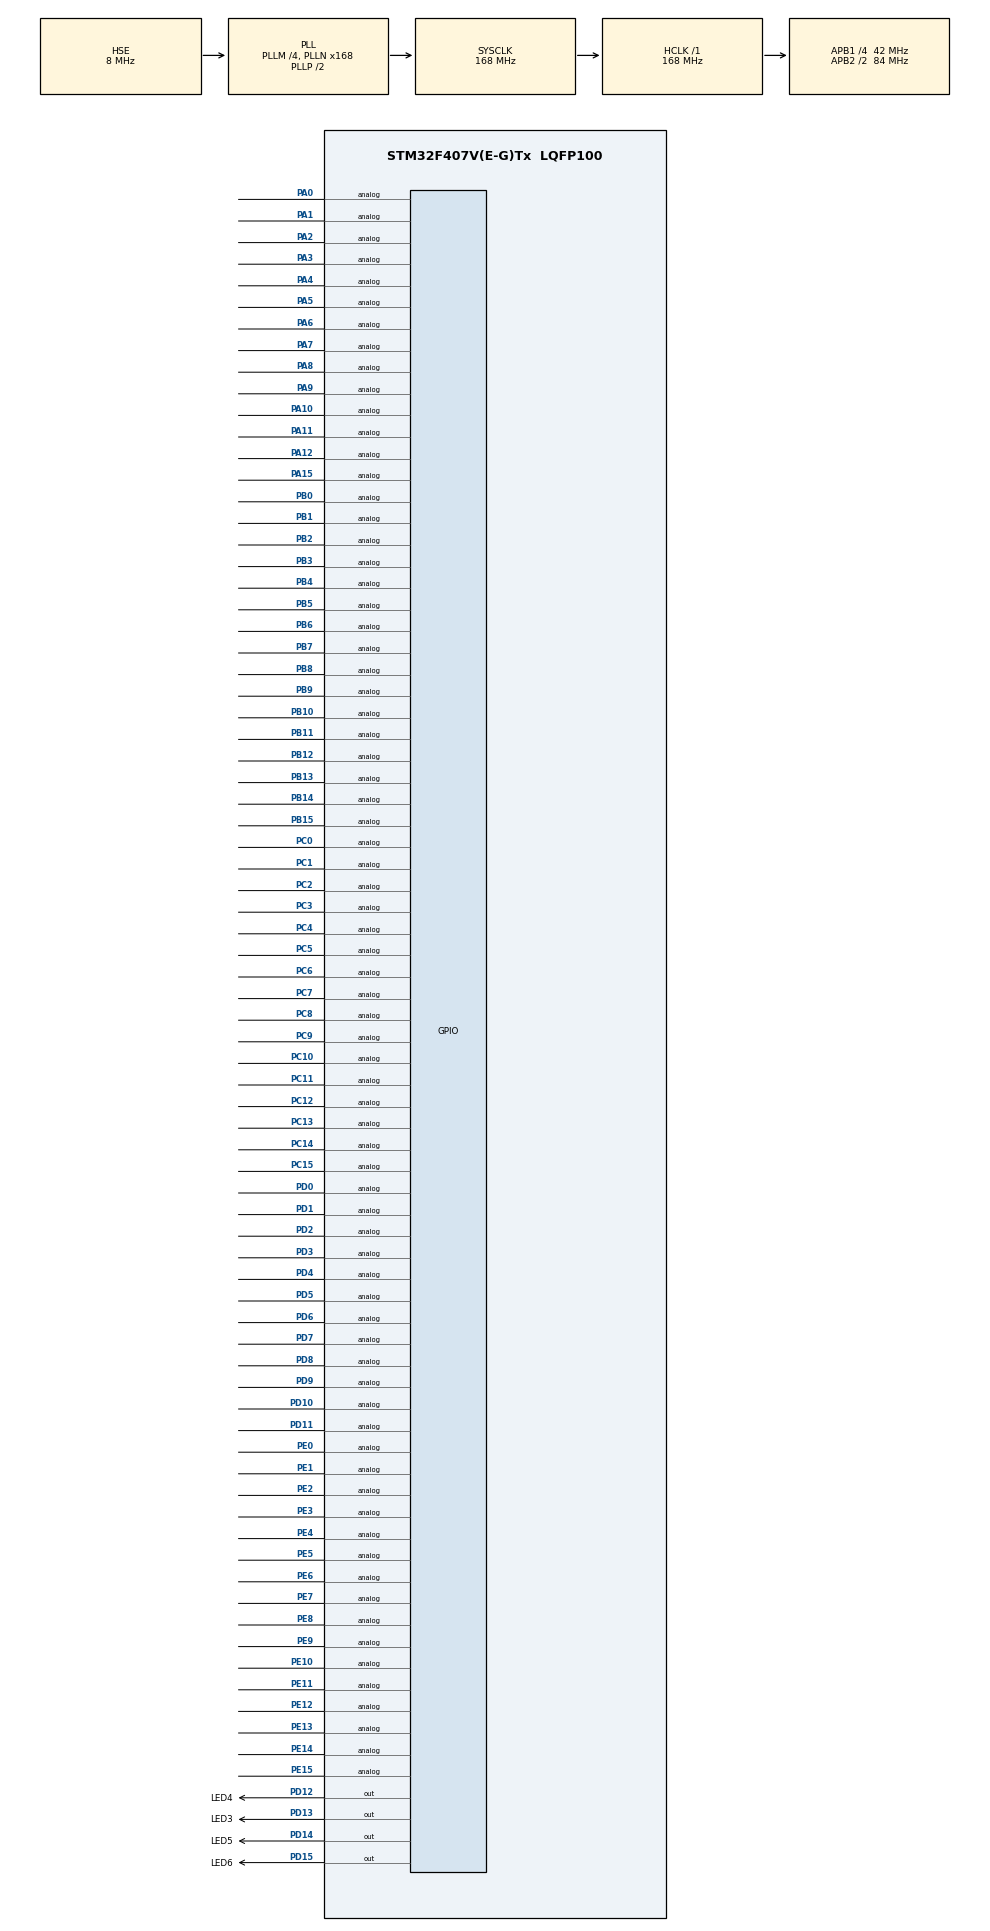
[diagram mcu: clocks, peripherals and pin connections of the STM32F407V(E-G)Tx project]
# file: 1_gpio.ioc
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Mcu.Family=STM32F4
Mcu.Name=STM32F407V(E-G)Tx
Mcu.Package=LQFP100
NVIC.PriorityGroup=NVIC_PRIORITYGROUP_4
PA0-WKUP.Signal=GPIO_Analog
PA1.Signal=GPIO_Analog
PA10.Signal=GPIO_Analog
PA11.Signal=GPIO_Analog
PA12.Signal=GPIO_Analog
PA13.Mode=Serial_Wire
PA13.Signal=SYS_JTMS-SWDIO
PA14.Mode=Serial_Wire
PA14.Signal=SYS_JTCK-SWCLK
PA15.Signal=GPIO_Analog
PA2.Signal=GPIO_Analog
PA3.Signal=GPIO_Analog
PA4.Signal=GPIO_Analog
PA5.Signal=GPIO_Analog
PA6.Signal=GPIO_Analog
PA7.Signal=GPIO_Analog
PA8.Signal=GPIO_Analog
PA9.Signal=GPIO_Analog
PB0.Signal=GPIO_Analog
PB1.Signal=GPIO_Analog
PB10.Signal=GPIO_Analog
PB11.Signal=GPIO_Analog
PB12.Signal=GPIO_Analog
PB13.Signal=GPIO_Analog
PB14.Signal=GPIO_Analog
PB15.Signal=GPIO_Analog
PB2.Signal=GPIO_Analog
PB3.Signal=GPIO_Analog
PB4.Signal=GPIO_Analog
PB5.Signal=GPIO_Analog
PB6.Signal=GPIO_Analog
PB7.Signal=GPIO_Analog
PB8.Signal=GPIO_Analog
PB9.Signal=GPIO_Analog
PC0.Signal=GPIO_Analog
PC1.Signal=GPIO_Analog
PC10.Signal=GPIO_Analog
PC11.Signal=GPIO_Analog
PC12.Signal=GPIO_Analog
PC13-ANTI_TAMP.Signal=GPIO_Analog
PC14-OSC32_IN.Signal=GPIO_Analog
PC15-OSC32_OUT.Signal=GPIO_Analog
PC2.Signal=GPIO_Analog
PC3.Signal=GPIO_Analog
PC4.Signal=GPIO_Analog
PC5.Signal=GPIO_Analog
PC6.Signal=GPIO_Analog
PC7.Signal=GPIO_Analog
PC8.Signal=GPIO_Analog
PC9.Signal=GPIO_Analog
PD0.Signal=GPIO_Analog
PD1.Signal=GPIO_Analog
PD10.Signal=GPIO_Analog
PD11.Signal=GPIO_Analog
PD12.GPIO_Label=LED4
PD12.GPIO_Speed=GPIO_SPEED_FREQ_HIGH
PD12.Signal=GPIO_Output
PD13.GPIO_Label=LED3
PD13.GPIO_Speed=GPIO_SPEED_FREQ_HIGH
PD13.Signal=GPIO_Output
PD14.GPIO_Label=LED5
PD14.GPIO_Speed=GPIO_SPEED_FREQ_HIGH
PD14.Signal=GPIO_Output
PD15.GPIO_Label=LED6
PD15.GPIO_Speed=GPIO_SPEED_FREQ_HIGH
PD15.Signal=GPIO_Output
PD2.Signal=GPIO_Analog
PD3.Signal=GPIO_Analog
PD4.Signal=GPIO_Analog
PD5.Signal=GPIO_Analog
PD6.Signal=GPIO_Analog
PD7.Signal=GPIO_Analog
PD8.Signal=GPIO_Analog
PD9.Signal=GPIO_Analog
PE0.Signal=GPIO_Analog
PE1.Signal=GPIO_Analog
PE10.Signal=GPIO_Analog
PE11.Signal=GPIO_Analog
PE12.Signal=GPIO_Analog
PE13.Signal=GPIO_Analog
PE14.Signal=GPIO_Analog
PE15.Signal=GPIO_Analog
PE2.Signal=GPIO_Analog
PE3.Signal=GPIO_Analog
PE4.Signal=GPIO_Analog
PE5.Signal=GPIO_Analog
PE6.Signal=GPIO_Analog
PE7.Signal=GPIO_Analog
PE8.Signal=GPIO_Analog
PE9.Signal=GPIO_Analog
PH0-OSC_IN.Mode=HSE-External-Oscillator
PH0-OSC_IN.Signal=RCC_OSC_IN
PH1-OSC_OUT.Mode=HSE-External-Oscillator
PH1-OSC_OUT.Signal=RCC_OSC_OUT
ProjectManager.HeapSize=0x2000
ProjectManager.StackSize=0x4000
ProjectManager.TargetToolchain=MDK-ARM V5.27
RCC.48MHZClocksFreq_Value=84000000
RCC.AHBFreq_Value=168000000
RCC.APB1CLKDivider=RCC_HCLK_DIV4
RCC.APB1Freq_Value=42000000
RCC.APB1TimFreq_Value=84000000
RCC.APB2CLKDivider=RCC_HCLK_DIV2
RCC.APB2Freq_Value=84000000
RCC.APB2TimFreq_Value=168000000
RCC.CortexFreq_Value=168000000
RCC.HCLKFreq_Value=168000000
RCC.HSE_VALUE=8000000
RCC.HSI_VALUE=16000000
RCC.LSE_VALUE=32768
RCC.PLLM=4
RCC.PLLN=168
RCC.PLLSourceVirtual=RCC_PLLSOURCE_HSE
RCC.SYSCLKFreq_VALUE=168000000
RCC.SYSCLKSource=RCC_SYSCLKSOURCE_PLLCLK
RCC.VCOOutputFreq_Value=336000000
board=custom

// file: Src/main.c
/* USER CODE BEGIN Header */
/**
  ******************************************************************************
  * @file           : main.c
  * @brief          : Main program body
  ******************************************************************************
  * @attention
  *
  * <h2><center>&copy; Copyright (c) 2020 STMicroelectronics.
  * All rights reserved.</center></h2>
  *
  * This software component is licensed by ST under BSD 3-Clause license,
  * the "License"; You may not use this file except in compliance with the
  * License. You may obtain a copy of the License at:
  *                        opensource.org/licenses/BSD-3-Clause
  *
  ******************************************************************************
  */
/* USER CODE END Header */

#include "main.h"
#include "gpio.h"

void SystemClock_Config(void);

int main(void)
{

  /* MCU Configuration--------------------------------------------------------*/

  /* Reset of all peripherals, Initializes the Flash interface and the Systick. */
  HAL_Init();

  /* Configure the system clock */
  SystemClock_Config();

  /* Initialize all configured peripherals */
  MX_GPIO_Init();

  /* Infinite loop */
  /* USER CODE BEGIN WHILE */
  while (1)
  {
		HAL_GPIO_WritePin(LED3_GPIO_Port, LED3_Pin, GPIO_PIN_SET);
		HAL_Delay(500);
		HAL_GPIO_WritePin(LED3_GPIO_Port, LED3_Pin, GPIO_PIN_RESET);
		HAL_Delay(500);
		HAL_GPIO_WritePin(LED5_GPIO_Port, LED5_Pin, GPIO_PIN_SET);
		HAL_Delay(500);
		HAL_GPIO_WritePin(LED5_GPIO_Port, LED5_Pin, GPIO_PIN_RESET);
		HAL_Delay(500);
		HAL_GPIO_WritePin(LED6_GPIO_Port, LED6_Pin, GPIO_PIN_SET);
		HAL_Delay(500);
		HAL_GPIO_WritePin(LED6_GPIO_Port, LED6_Pin, GPIO_PIN_RESET);
		HAL_Delay(500);
		HAL_GPIO_WritePin(LED4_GPIO_Port, LED4_Pin, GPIO_PIN_SET);
		HAL_Delay(500);
		HAL_GPIO_WritePin(LED4_GPIO_Port, LED4_Pin, GPIO_PIN_RESET);
		HAL_Delay(500);
    /* USER CODE END WHILE */

  }
}

void SystemClock_Config(void)
{
  RCC_OscInitTypeDef RCC_OscInitStruct = {0};
  RCC_ClkInitTypeDef RCC_ClkInitStruct = {0};

  /** Configure the main internal regulator output voltage
  */
  __HAL_RCC_PWR_CLK_ENABLE();
  __HAL_PWR_VOLTAGESCALING_CONFIG(PWR_REGULATOR_VOLTAGE_SCALE1);
  /** Initializes the CPU, AHB and APB busses clocks
  */
  RCC_OscInitStruct.OscillatorType = RCC_OSCILLATORTYPE_HSE;
  RCC_OscInitStruct.HSEState = RCC_HSE_ON;
  RCC_OscInitStruct.PLL.PLLState = RCC_PLL_ON;
  RCC_OscInitStruct.PLL.PLLSource = RCC_PLLSOURCE_HSE;
  RCC_OscInitStruct.PLL.PLLM = 4;
  RCC_OscInitStruct.PLL.PLLN = 168;
  RCC_OscInitStruct.PLL.PLLP = RCC_PLLP_DIV2;
  RCC_OscInitStruct.PLL.PLLQ = 4;
  if (HAL_RCC_OscConfig(&RCC_OscInitStruct) != HAL_OK)
  {
    Error_Handler();
  }
  /** Initializes the CPU, AHB and APB busses clocks
  */
  RCC_ClkInitStruct.ClockType = RCC_CLOCKTYPE_HCLK|RCC_CLOCKTYPE_SYSCLK
                              |RCC_CLOCKTYPE_PCLK1|RCC_CLOCKTYPE_PCLK2;
  RCC_ClkInitStruct.SYSCLKSource = RCC_SYSCLKSOURCE_PLLCLK;
  RCC_ClkInitStruct.AHBCLKDivider = RCC_SYSCLK_DIV1;
  RCC_ClkInitStruct.APB1CLKDivider = RCC_HCLK_DIV4;
  RCC_ClkInitStruct.APB2CLKDivider = RCC_HCLK_DIV2;

  if (HAL_RCC_ClockConfig(&RCC_ClkInitStruct, FLASH_LATENCY_5) != HAL_OK)
  {
    Error_Handler();
  }
}

void Error_Handler(void)
{
}

/************************ (C) COPYRIGHT STMicroelectronics *****END OF FILE****/
